VERSION ""

NS_ :

BS_:

BU_:
VAL_TABLE_ Accleration 1 "cut" 0 "connect" ;
VAL_TABLE_ RearBrakeValveState 2 "NotPressed" 1 "Released" 0 "Applied" ;
VAL_TABLE_ FrontBrakeValveState 2 "NotPressed" 1 "Released" 0 "Applied" ;
VAL_TABLE_ Pump_Status 2 "Error" 1 "On" 0 "Off" ;
VAL_TABLE_ ABS_Status 2 "Error" 1 "Active" 0 "InActive" ;

BO_ 258 AcclerationStatus: 8 Vector__XXX
 SG_ AcclerationStatus : 0|2@1- (1,0) [-2|1] "" Vector__XXX

BO_ 272 BrakeState: 8 Vector__XXX
 SG_ Brake : 0|8@1+ (1,0) [0|1000] "" Vector__XXX

BO_ 257 RearWheelSpeed: 1 Vector__XXX
 SG_ RearWheelSpeed : 0|8@1+ (4,0) [0|140] "KMPH" Vector__XXX

BO_ 256 FrontWheelSpeed: 1 Vector__XXX
 SG_ FrontWheelSpeed : 0|12@1+ (1,0) [0|140] "KMPH" Vector__XXX

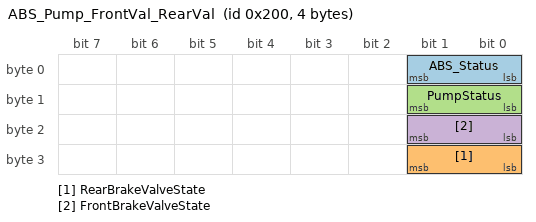
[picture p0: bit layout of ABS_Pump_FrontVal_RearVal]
BO_ 512 ABS_Pump_FrontVal_RearVal: 4 Vector__XXX
 SG_ ABS_Status : 0|2@1+ (1,0) [0|2] "" Vector__XXX
 SG_ RearBrakeValveState : 24|2@1+ (1,0) [0|2] "" Vector__XXX
 SG_ PumpStatus : 8|2@1+ (1,0) [0|2] "" Vector__XXX
 SG_ FrontBrakeValveState : 16|2@1+ (1,0) [0|2] "" Vector__XXX

BA_DEF_  "BusType" STRING ;
BA_DEF_DEF_  "BusType" "CAN";
VAL_ 258 AcclerationStatus 1 "cut" 0 "connect" ;
VAL_ 512 ABS_Status 2 "Error" 1 "Active" 0 "InActive" ;
VAL_ 512 RearBrakeValveState 2 "NotPressed" 1 "Released" 0 "Applied" ;
VAL_ 512 PumpStatus 2 "Error" 1 "On" 0 "Off" ;
VAL_ 512 FrontBrakeValveState 2 "NotPressed" 1 "Released" 0 "Applied" ;
